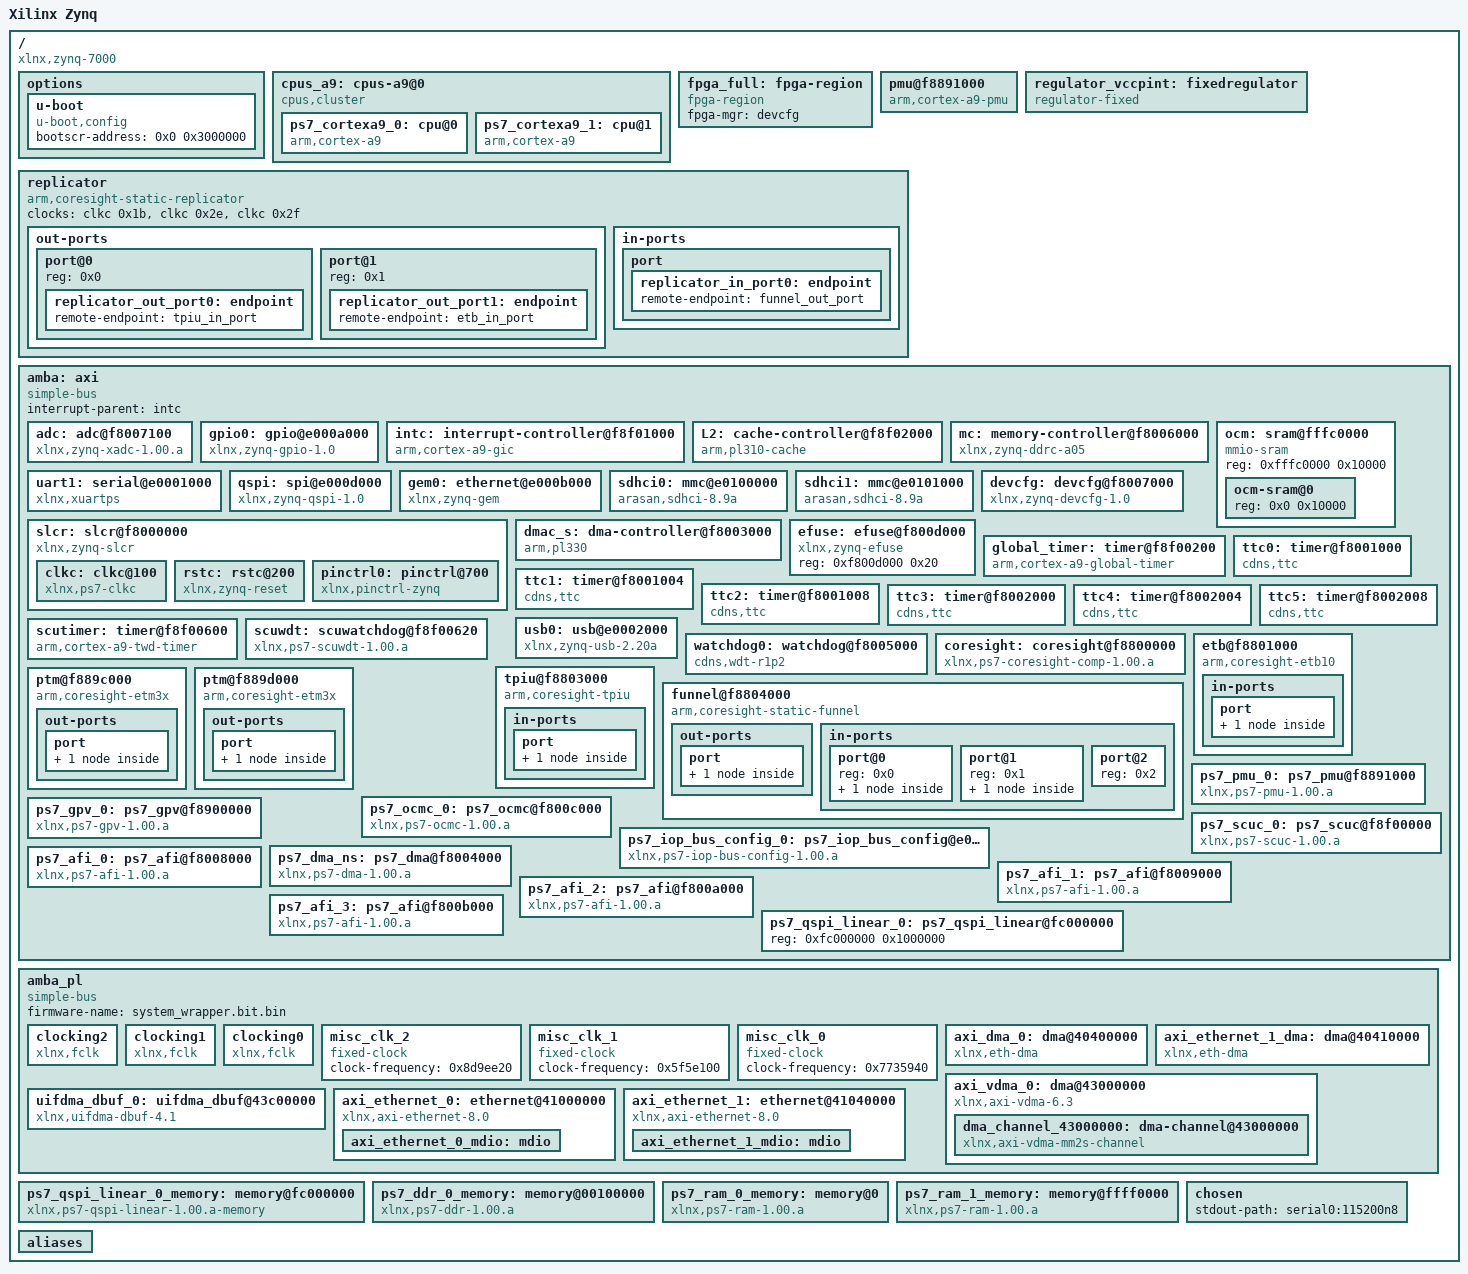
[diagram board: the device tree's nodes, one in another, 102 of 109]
/dts-v1/;
/ {
        #address-cells = <0x1>;
        #size-cells = <0x1>;
        compatible = "xlnx,zynq-7000";
        model = "Xilinx Zynq";
        device_id = "7z020";
        slrcount = <0x1>;
        family = "Zynq";
        speed_grade = "2";
        pruned-sdt = <0x1>;

        options {

                u-boot {
                        compatible = "u-boot,config";
                        bootscr-address = <0x0 0x3000000>;
                };
        };

        cpus_a9: cpus-a9@0 {
                phandle = <0x39>;
                #address-cells = <0x1>;
                #size-cells = <0x0>;
                compatible = "cpus,cluster";
                address-map = <0xf0000000 &amba 0xf0000000 0x10000000>,
                 <0x100000 &ps7_ddr_0_memory 0x100000 0x3ff00000>,
                 <0x0 &ps7_ram_0_memory 0x0 0x30000>,
                 <0xffff0000 &ps7_ram_1_memory 0xffff0000 0xfe00>,
                 <0x40400000 &axi_dma_0 0x40400000 0x10000>,
                 <0x40410000 &axi_ethernet_1_dma 0x40410000 0x10000>,
                 <0x41000000 &axi_ethernet_0 0x41000000 0x40000>,
                 <0x41040000 &axi_ethernet_1 0x41040000 0x40000>,
                 <0x43000000 &axi_vdma_0 0x43000000 0x10000>,
                 <0x43c00000 &uifdma_dbuf_0 0x43c00000 0x10000>,
                 <0xf8008000 &ps7_afi_0 0xf8008000 0x1000>,
                 <0xf8009000 &ps7_afi_1 0xf8009000 0x1000>,
                 <0xf800a000 &ps7_afi_2 0xf800a000 0x1000>,
                 <0xf800b000 &ps7_afi_3 0xf800b000 0x1000>,
                 <0xf8800000 &coresight 0xf8800000 0x100000>,
                 <0xf8006000 &mc 0xf8006000 0x1000>,
                 <0xf8007000 &devcfg 0xf8007000 0x100>,
                 <0xf8004000 &ps7_dma_ns 0xf8004000 0x1000>,
                 <0xf8003000 &dmac_s 0xf8003000 0x1000>,
                 <0xe000b000 &gem0 0xe000b000 0x1000>,
                 <0xf8f00200 &global_timer 0xf8f00200 0x100>,
                 <0xe000a000 &gpio0 0xe000a000 0x1000>,
                 <0xf8900000 &ps7_gpv_0 0xf8900000 0x100000>,
                 <0xf8f01000 &intc 0xf8f01000 0x1000>,
                 <0xe0200000 &ps7_iop_bus_config_0 0xe0200000 0x1000>,
                 <0xf8f02000 &L2 0xf8f02000 0x1000>,
                 <0xf800c000 &ps7_ocmc_0 0xf800c000 0x1000>,
                 <0xf8891000 &ps7_pmu_0 0xf8891000 0x1000>,
                 <0xe000d000 &qspi 0xe000d000 0x1000>,
                 <0xfc000000 &ps7_qspi_linear_0_memory 0xfc000000 0x1000000>,
                 <0xf8f00000 &ps7_scuc_0 0xf8f00000 0xfd>,
                 <0xf8f00600 &scutimer 0xf8f00600 0x20>,
                 <0xf8f00620 &scuwdt 0xf8f00620 0xe0>,
                 <0xe0100000 &sdhci0 0xe0100000 0x1000>,
                 <0xe0101000 &sdhci1 0xe0101000 0x1000>,
                 <0xf8000000 &slcr 0xf8000000 0x1000>,
                 <0xe0001000 &uart1 0xe0001000 0x1000>,
                 <0xe0002000 &usb0 0xe0002000 0x1000>,
                 <0xf8007100 &adc 0xf8007100 0x21>;
                #ranges-address-cells = <0x1>;
                #ranges-size-cells = <0x1>;

                ps7_cortexa9_0: cpu@0 {
                        phandle = <0x32>;
                        compatible = "arm,cortex-a9";
                        device_type = "cpu";
                        reg = <0x0>;
                        clocks = <&clkc 0x3>;
                        clock-latency = <0x3e8>;
                        cpu0-supply = <&regulator_vccpint>;
                        operating-points = <0xa2c2b 0xf4240 0x51616 0xf4240>;
                        xlnx,i-cache-size = <0x8000>;
                        xlnx,d-cache-line-size = <0x14>;
                        xlnx,i-cache-line-size = <0x14>;
                        xlnx,cpu-1x-clk-freq-hz = <0x69f6bcb>;
                        xlnx,ip-name = "ps7_cortexa9";
                        xlnx,d-cache-size = <0x8000>;
                        xlnx,num-cores = <0x2>;
                        xlnx,cpu-clk-freq-hz = <0x27bc86bf>;
                        bus-handle = <0x1>;
                };

                ps7_cortexa9_1: cpu@1 {
                        phandle = <0x34>;
                        compatible = "arm,cortex-a9";
                        device_type = "cpu";
                        reg = <0x1>;
                        clocks = <&clkc 0x3>;
                        xlnx,i-cache-size = <0x8000>;
                        xlnx,d-cache-line-size = <0x14>;
                        xlnx,i-cache-line-size = <0x14>;
                        xlnx,cpu-1x-clk-freq-hz = <0x69f6bcb>;
                        xlnx,ip-name = "ps7_cortexa9";
                        xlnx,d-cache-size = <0x8000>;
                        xlnx,cpu-clk-freq-hz = <0x27bc86bf>;
                        bus-handle = <0x1>;
                };
        };

        fpga_full: fpga-region {
                phandle = <0x3a>;
                compatible = "fpga-region";
                fpga-mgr = <&devcfg>;
                #address-cells = <0x1>;
                #size-cells = <0x1>;
                ranges;
        };

        pmu@f8891000 {
                compatible = "arm,cortex-a9-pmu";
                interrupts = <0x0 0x5 0x4 0x0 0x6 0x4>;
                interrupt-parent = <&intc>;
                reg = <0xf8891000 0x1000 0xf8893000 0x1000>;
        };

        regulator_vccpint: fixedregulator {
                phandle = <0x29>;
                compatible = "regulator-fixed";
                regulator-name = "VCCPINT";
                regulator-min-microvolt = <0xf4240>;
                regulator-max-microvolt = <0xf4240>;
                regulator-boot-on;
                regulator-always-on;
        };

        replicator {
                compatible = "arm,coresight-static-replicator";
                clocks = <&clkc 0x1b>,
                 <&clkc 0x2e>,
                 <&clkc 0x2f>;
                clock-names = "apb_pclk", "dbg_trc", "dbg_apb";

                out-ports {
                        #address-cells = <0x1>;
                        #size-cells = <0x0>;

                        port@0 {
                                reg = <0x0>;

                                replicator_out_port0: endpoint {
                                        phandle = <0x2e>;
                                        remote-endpoint = <&tpiu_in_port>;
                                };
                        };

                        port@1 {
                                reg = <0x1>;

                                replicator_out_port1: endpoint {
                                        phandle = <0x2d>;
                                        remote-endpoint = <&etb_in_port>;
                                };
                        };
                };

                in-ports {

                        port {

                                replicator_in_port0: endpoint {
                                        phandle = <0x2f>;
                                        remote-endpoint = <&funnel_out_port>;
                                };
                        };
                };
        };

        amba: axi {
                phandle = <0x1>;
                bootph-all;
                compatible = "simple-bus";
                #address-cells = <0x1>;
                #size-cells = <0x1>;
                interrupt-parent = <&intc>;
                ranges;

                adc: adc@f8007100 {
                        phandle = <0x27>;
                        compatible = "xlnx,zynq-xadc-1.00.a";
                        reg = <0xf8007100 0x20>;
                        interrupts = <0x0 0x7 0x4>;
                        interrupt-parent = <&intc>;
                        clocks = <&clkc 0xc>;
                        status = "okay";
                        xlnx,ip-name = "ps7_xadc";
                        xlnx,name = "ps7_xadc_0";
                };

                gpio0: gpio@e000a000 {
                        phandle = <0x16>;
                        compatible = "xlnx,zynq-gpio-1.0";
                        #gpio-cells = <0x2>;
                        clocks = <&clkc 0x2a>;
                        gpio-controller;
                        interrupt-controller;
                        #interrupt-cells = <0x2>;
                        interrupt-parent = <&intc>;
                        interrupts = <0x0 0x14 0x4>;
                        reg = <0xe000a000 0x1000>;
                        xlnx,mio-gpio-mask = <0x5600>;
                        status = "okay";
                        gpio-mask-high = <0x0>;
                        xlnx,emio-gpio-width = <0x40>;
                        xlnx,ip-name = "ps7_gpio";
                        gpio-mask-low = <0x5600>;
                        emio-gpio-width = <0x40>;
                        xlnx,name = "ps7_gpio_0";
                };

                intc: interrupt-controller@f8f01000 {
                        phandle = <0x18>;
                        compatible = "arm,cortex-a9-gic";
                        #interrupt-cells = <0x3>;
                        interrupt-controller;
                        reg = <0xf8f01000 0x1000 0xf8f00100 0x100>;
                        status = "okay";
                        xlnx,irq-f2p-mode = "DIRECT";
                        xlnx,ip-name = "ps7_intc_dist";
                        xlnx,name = "ps7_intc_dist_0";
                };

                L2: cache-controller@f8f02000 {
                        phandle = <0x1a>;
                        compatible = "arm,pl310-cache";
                        reg = <0xf8f02000 0x1000>;
                        interrupts = <0x0 0x2 0x4>;
                        arm,data-latency = <0x3 0x2 0x2>;
                        arm,tag-latency = <0x2 0x2 0x2>;
                        cache-unified;
                        cache-level = <0x2>;
                        status = "okay";
                        xlnx,ip-name = "ps7_pl310";
                        xlnx,name = "ps7_pl310_0";
                };

                mc: memory-controller@f8006000 {
                        phandle = <0x10>;
                        compatible = "xlnx,zynq-ddrc-a05";
                        reg = <0xf8006000 0x1000>;
                        status = "okay";
                        xlnx,ddr-clk-freq-hz = <0x1fca057e>;
                        xlnx,ip-name = "ps7_ddrc";
                        xlnx,has-ecc = <0x0>;
                        xlnx,name = "ps7_ddrc_0";
                };

                ocm: sram@fffc0000 {
                        phandle = <0x3f>;
                        compatible = "mmio-sram";
                        reg = <0xfffc0000 0x10000>;
                        #address-cells = <0x1>;
                        #size-cells = <0x1>;
                        ranges = <0x0 0xfffc0000 0x10000>;

                        ocm-sram@0 {
                                reg = <0x0 0x10000>;
                        };
                };

                uart1: serial@e0001000 {
                        phandle = <0x25>;
                        compatible = "xlnx,xuartps", "cdns,uart-r1p8";
                        status = "okay";
                        clocks = <&clkc 0x18>,
                         <&clkc 0x29>;
                        clock-names = "uart_clk", "pclk";
                        reg = <0xe0001000 0x1000>;
                        interrupts = <0x0 0x32 0x4>;
                        interrupt-parent = <&intc>;
                        xlnx,clock-freq = <0x5f5e100>;
                        xlnx,has-modem = <0x0>;
                        xlnx,ip-name = "ps7_uart";
                        cts-override;
                        port-number = <0x0>;
                        xlnx,uart-clk-freq-hz = <0x5f5e100>;
                        xlnx,name = "ps7_uart_1";
                };

                qspi: spi@e000d000 {
                        phandle = <0x1d>;
                        compatible = "xlnx,zynq-qspi-1.0";
                        reg = <0xe000d000 0x1000>;
                        interrupt-parent = <&intc>;
                        interrupts = <0x0 0x13 0x4>;
                        clocks = <&clkc 0xa>,
                         <&clkc 0x2b>;
                        clock-names = "ref_clk", "pclk";
                        status = "okay";
                        #address-cells = <0x1>;
                        #size-cells = <0x0>;
                        xlnx,qspi-fbclk = <0x0>;
                        num-cs = <0x1>;
                        xlnx,qspi-clk-freq-hz = <0x7735940>;
                        xlnx,bus-width = <0x2>;
                        xlnx,ip-name = "ps7_qspi";
                        spi-rx-bus-width = <0x4>;
                        xlnx,connection-mode = <0x0>;
                        spi-tx-bus-width = <0x4>;
                        xlnx,clock-freq = <0x7735940>;
                        xlnx,fb-clk = <0x1>;
                        xlnx,qspi-mode = <0x0>;
                        xlnx,name = "ps7_qspi_0";
                        xlnx,qspi-bus-width = <0x2>;
                        is-dual = <0x0>;
                };

                gem0: ethernet@e000b000 {
                        phandle = <0x14>;
                        compatible = "xlnx,zynq-gem", "cdns,gem";
                        reg = <0xe000b000 0x1000>;
                        status = "okay";
                        interrupts = <0x0 0x16 0x4>;
                        interrupt-parent = <&intc>;
                        clocks = <&clkc 0x1e>,
                         <&clkc 0x1e>,
                         <&clkc 0xd>;
                        clock-names = "pclk", "hclk", "tx_clk";
                        #address-cells = <0x1>;
                        #size-cells = <0x0>;
                        xlnx,has-mdio = <0x1>;
                        phy-mode = "rgmii-id";
                        xlnx,enet-slcr-1000mbps-div0 = <0x8>;
                        xlnx,enet-slcr-10mbps-div0 = <0x8>;
                        xlnx,enet-slcr-1000mbps-div1 = <0x1>;
                        xlnx,enet-slcr-10mbps-div1 = <0x32>;
                        xlnx,ip-name = "ps7_ethernet";
                        xlnx,eth-mode = <0x1>;
                        xlnx,enet-clk-freq-hz = <0x7735940>;
                        xlnx,enet-slcr-100mbps-div0 = <0x8>;
                        xlnx,ptp-enet-clock = <0x69f6bcb>;
                        xlnx,enet-slcr-100mbps-div1 = <0x5>;
                        xlnx,name = "ps7_ethernet_0";
                };

                sdhci0: mmc@e0100000 {
                        phandle = <0x22>;
                        compatible = "arasan,sdhci-8.9a";
                        status = "okay";
                        clock-names = "clk_xin", "clk_ahb";
                        clocks = <&clkc 0x15>,
                         <&clkc 0x20>;
                        interrupt-parent = <&intc>;
                        interrupts = <0x0 0x18 0x4>;
                        reg = <0xe0100000 0x1000>;
                        xlnx,has-power = <0x0>;
                        xlnx,ip-name = "ps7_sdio";
                        xlnx,sdio-clk-freq-hz = <0x2faf080>;
                        xlnx,has-wp = <0x0>;
                        xlnx,has-cd = <0x1>;
                        xlnx,name = "ps7_sd_0";
                };

                sdhci1: mmc@e0101000 {
                        phandle = <0x23>;
                        compatible = "arasan,sdhci-8.9a";
                        status = "okay";
                        clock-names = "clk_xin", "clk_ahb";
                        clocks = <&clkc 0x16>,
                         <&clkc 0x21>;
                        interrupt-parent = <&intc>;
                        interrupts = <0x0 0x2f 0x4>;
                        reg = <0xe0101000 0x1000>;
                        xlnx,has-power = <0x0>;
                        xlnx,ip-name = "ps7_sdio";
                        xlnx,sdio-clk-freq-hz = <0x2faf080>;
                        xlnx,has-wp = <0x0>;
                        xlnx,has-cd = <0x1>;
                        xlnx,name = "ps7_sd_1";
                };

                slcr: slcr@f8000000 {
                        phandle = <0x24>;
                        bootph-all;
                        #address-cells = <0x1>;
                        #size-cells = <0x1>;
                        compatible = "xlnx,zynq-slcr", "syscon", "simple-mfd";
                        reg = <0xf8000000 0x1000>;
                        ranges;
                        status = "okay";
                        xlnx,ip-name = "ps7_slcr";
                        xlnx,name = "ps7_slcr_0";

                        clkc: clkc@100 {
                                phandle = <0x28>;
                                bootph-all;
                                #clock-cells = <0x1>;
                                compatible = "xlnx,ps7-clkc";
                                fclk-enable = <0x7>;
                                clock-output-names = "armpll", "ddrpll", "iopll", "cpu_6or4x", "cpu_3or2x", "cpu_2x", "cpu_1x", "ddr2x", "ddr3x", "dci", "lqspi", "smc", "pcap", "gem0", "gem1", "fclk0", "fclk1", "fclk2", "fclk3", "can0", "can1", "sdio0", "sdio1", "uart0", "uart1", "spi0", "spi1", "dma", "usb0_aper", "usb1_aper", "gem0_aper", "gem1_aper", "sdio0_aper", "sdio1_aper", "spi0_aper", "spi1_aper", "can0_aper", "can1_aper", "i2c0_aper", "i2c1_aper", "uart0_aper", "uart1_aper", "gpio_aper", "lqspi_aper", "smc_aper", "swdt", "dbg_trc", "dbg_apb";
                                reg = <0x100 0x100>;
                                ps-clk-frequency = <0x1fca055>;
                        };

                        rstc: rstc@200 {
                                phandle = <0x47>;
                                compatible = "xlnx,zynq-reset";
                                reg = <0x200 0x48>;
                                #reset-cells = <0x1>;
                                syscon = <&slcr>;
                        };

                        pinctrl0: pinctrl@700 {
                                phandle = <0x48>;
                                compatible = "xlnx,pinctrl-zynq";
                                reg = <0x700 0x200>;
                                syscon = <&slcr>;
                        };
                };

                dmac_s: dma-controller@f8003000 {
                        phandle = <0x13>;
                        compatible = "arm,pl330", "arm,primecell";
                        reg = <0xf8003000 0x1000>;
                        interrupt-parent = <&intc>;
                        interrupts = <0x0 0xd 0x4 0x0 0xe 0x4 0x0 0xf 0x4 0x0 0x10 0x4 0x0 0x11 0x4 0x0 0x28 0x4 0x0 0x29 0x4 0x0 0x2a 0x4 0x0 0x2b 0x4>;
                        #dma-cells = <0x1>;
                        clocks = <&clkc 0x1b>;
                        clock-names = "apb_pclk";
                        status = "okay";
                        xlnx,ip-name = "ps7_dma";
                        xlnx,is-secure;
                        xlnx,name = "ps7_dma_s";
                };

                devcfg: devcfg@f8007000 {
                        phandle = <0x11>;
                        compatible = "xlnx,zynq-devcfg-1.0";
                        reg = <0xf8007000 0x100>;
                        interrupt-parent = <&intc>;
                        interrupts = <0x0 0x8 0x4>;
                        clocks = <&clkc 0xc>,
                         <&clkc 0xf>,
                         <&clkc 0x10>,
                         <&clkc 0x11>,
                         <&clkc 0x12>;
                        clock-names = "ref_clk", "fclk0", "fclk1", "fclk2", "fclk3";
                        syscon = <&slcr>;
                        status = "okay";
                        xlnx,ip-name = "ps7_dev_cfg";
                        xlnx,name = "ps7_dev_cfg_0";
                };

                efuse: efuse@f800d000 {
                        phandle = <0x49>;
                        compatible = "xlnx,zynq-efuse";
                        reg = <0xf800d000 0x20>;
                };

                global_timer: timer@f8f00200 {
                        phandle = <0x15>;
                        compatible = "arm,cortex-a9-global-timer";
                        reg = <0xf8f00200 0x20>;
                        interrupts = <0x1 0xb 0x301>;
                        interrupt-parent = <&intc>;
                        clocks = <&clkc 0x4>;
                        status = "okay";
                        xlnx,ip-name = "ps7_globaltimer";
                        xlnx,name = "ps7_globaltimer_0";
                };

                ttc0: timer@f8001000 {
                        phandle = <0x4a>;
                        interrupt-parent = <&intc>;
                        interrupts = <0x0 0xa 0x4 0x0 0xb 0x4 0x0 0xc 0x4>;
                        compatible = "cdns,ttc";
                        clocks = <&clkc 0x6>;
                        reg = <0xf8001000 0x1000>;
                };

                ttc1: timer@f8001004 {
                        phandle = <0x5c>;
                        reg = <0xf8001004 0xffc>;
                        clocks = <&clkc 0x6>;
                        compatible = "cdns,ttc";
                        interrupts = <0x0 0xb 0x4 0x0 0xc 0x4>;
                        interrupt-parent = <&intc>;
                        lop-dynamic-ttc-node = <0x1>;
                };

                ttc2: timer@f8001008 {
                        phandle = <0x5d>;
                        reg = <0xf8001008 0xff8>;
                        clocks = <&clkc 0x6>;
                        compatible = "cdns,ttc";
                        interrupts = <0x0 0xc 0x4>;
                        interrupt-parent = <&intc>;
                        lop-dynamic-ttc-node = <0x1>;
                };

                ttc3: timer@f8002000 {
                        phandle = <0x4b>;
                        interrupt-parent = <&intc>;
                        interrupts = <0x0 0x25 0x4 0x0 0x26 0x4 0x0 0x27 0x4>;
                        compatible = "cdns,ttc";
                        clocks = <&clkc 0x6>;
                        reg = <0xf8002000 0x1000>;
                };

                ttc4: timer@f8002004 {
                        phandle = <0x5e>;
                        reg = <0xf8002004 0xffc>;
                        clocks = <&clkc 0x6>;
                        compatible = "cdns,ttc";
                        interrupts = <0x0 0x26 0x4 0x0 0x27 0x4>;
                        interrupt-parent = <&intc>;
                        lop-dynamic-ttc-node = <0x1>;
                };

                ttc5: timer@f8002008 {
                        phandle = <0x5f>;
                        reg = <0xf8002008 0xff8>;
                        clocks = <&clkc 0x6>;
                        compatible = "cdns,ttc";
                        interrupts = <0x0 0x27 0x4>;
                        interrupt-parent = <&intc>;
                        lop-dynamic-ttc-node = <0x1>;
                };

                scutimer: timer@f8f00600 {
                        phandle = <0x20>;
                        bootph-all;
                        interrupt-parent = <&intc>;
                        interrupts = <0x1 0xd 0x301>;
                        compatible = "arm,cortex-a9-twd-timer";
                        reg = <0xf8f00600 0x20>;
                        clocks = <&clkc 0x4>;
                        status = "okay";
                        xlnx,ip-name = "ps7_scutimer";
                        xlnx,name = "ps7_scutimer_0";
                };

                scuwdt: scuwatchdog@f8f00620 {
                        phandle = <0x21>;
                        interrupt-parent = <&intc>;
                        interrupts = <0x1 0xe 0x4>;
                        compatible = "xlnx,ps7-scuwdt-1.00.a";
                        reg = <0xf8f00620 0xe0>;
                        status = "okay";
                        xlnx,ip-name = "ps7_scuwdt";
                        xlnx,name = "ps7_scuwdt_0";
                };

                usb0: usb@e0002000 {
                        phandle = <0x26>;
                        compatible = "xlnx,zynq-usb-2.20a", "chipidea,usb2";
                        status = "okay";
                        clocks = <&clkc 0x1c>;
                        interrupt-parent = <&intc>;
                        interrupts = <0x0 0x15 0x4>;
                        reg = <0xe0002000 0x1000>;
                        phy_type = "ulpi";
                        xlnx,ip-name = "ps7_usb";
                        xlnx,enable-superspeed = <0x0>;
                        xlnx,name = "ps7_usb_0";
                };

                watchdog0: watchdog@f8005000 {
                        phandle = <0x4d>;
                        clocks = <&clkc 0x2d>;
                        compatible = "cdns,wdt-r1p2";
                        interrupt-parent = <&intc>;
                        interrupts = <0x0 0x9 0x1>;
                        reg = <0xf8005000 0x1000>;
                        timeout-sec = <0xa>;
                };

                coresight: coresight@f8800000 {
                        phandle = <0xf>;
                        compatible = "xlnx,ps7-coresight-comp-1.00.a";
                        status = "okay";
                        reg = <0xf8800000 0x100000>;
                        xlnx,ip-name = "ps7_coresight_comp";
                        xlnx,name = "ps7_coresight_comp_0";
                };

                etb@f8801000 {
                        compatible = "arm,coresight-etb10", "arm,primecell";
                        reg = <0xf8801000 0x1000>;
                        clocks = <&clkc 0x1b>,
                         <&clkc 0x2e>,
                         <&clkc 0x2f>;
                        clock-names = "apb_pclk", "dbg_trc", "dbg_apb";

                        in-ports {

                                port {

                                        etb_in_port: endpoint {
                                                phandle = <0x2b>;
                                                remote-endpoint = <&replicator_out_port1>;
                                        };
                                };
                        };
                };

                tpiu@f8803000 {
                        compatible = "arm,coresight-tpiu", "arm,primecell";
                        reg = <0xf8803000 0x1000>;
                        clocks = <&clkc 0x1b>,
                         <&clkc 0x2e>,
                         <&clkc 0x2f>;
                        clock-names = "apb_pclk", "dbg_trc", "dbg_apb";

                        in-ports {

                                port {

                                        tpiu_in_port: endpoint {
                                                phandle = <0x2a>;
                                                remote-endpoint = <&replicator_out_port0>;
                                        };
                                };
                        };
                };

                funnel@f8804000 {
                        compatible = "arm,coresight-static-funnel", "arm,primecell";
                        reg = <0xf8804000 0x1000>;
                        clocks = <&clkc 0x1b>,
                         <&clkc 0x2e>,
                         <&clkc 0x2f>;
                        clock-names = "apb_pclk", "dbg_trc", "dbg_apb";

                        out-ports {

                                port {

                                        funnel_out_port: endpoint {
                                                phandle = <0x2c>;
                                                remote-endpoint = <&replicator_in_port0>;
                                        };
                                };
                        };

                        in-ports {
                                #address-cells = <0x1>;
                                #size-cells = <0x0>;

                                port@0 {
                                        reg = <0x0>;

                                        funnel0_in_port0: endpoint {
                                                phandle = <0x33>;
                                                remote-endpoint = <&ptm0_out_port>;
                                        };
                                };

                                port@1 {
                                        reg = <0x1>;

                                        funnel0_in_port1: endpoint {
                                                phandle = <0x35>;
                                                remote-endpoint = <&ptm1_out_port>;
                                        };
                                };

                                port@2 {
                                        reg = <0x2>;
                                };
                        };
                };

                ptm@f889c000 {
                        compatible = "arm,coresight-etm3x", "arm,primecell";
                        reg = <0xf889c000 0x1000>;
                        clocks = <&clkc 0x1b>,
                         <&clkc 0x2e>,
                         <&clkc 0x2f>;
                        clock-names = "apb_pclk", "dbg_trc", "dbg_apb";
                        cpu = <&ps7_cortexa9_0>;

                        out-ports {

                                port {

                                        ptm0_out_port: endpoint {
                                                phandle = <0x30>;
                                                remote-endpoint = <&funnel0_in_port0>;
                                        };
                                };
                        };
                };

                ptm@f889d000 {
                        compatible = "arm,coresight-etm3x", "arm,primecell";
                        reg = <0xf889d000 0x1000>;
                        clocks = <&clkc 0x1b>,
                         <&clkc 0x2e>,
                         <&clkc 0x2f>;
                        clock-names = "apb_pclk", "dbg_trc", "dbg_apb";
                        cpu = <&ps7_cortexa9_1>;

                        out-ports {

                                port {

                                        ptm1_out_port: endpoint {
                                                phandle = <0x31>;
                                                remote-endpoint = <&funnel0_in_port1>;
                                        };
                                };
                        };
                };

                ps7_pmu_0: ps7_pmu@f8891000 {
                        phandle = <0x1c>;
                        compatible = "xlnx,ps7-pmu-1.00.a";
                        status = "okay";
                        xlnx,ip-name = "ps7_pmu";
                        reg = <0xf8891000 0x1000 0xf8893000 0x1000>;
                        xlnx,name = "ps7_pmu_0";
                };

                ps7_ocmc_0: ps7_ocmc@f800c000 {
                        phandle = <0x1b>;
                        compatible = "xlnx,ps7-ocmc-1.00.a";
                        status = "okay";
                        xlnx,ip-name = "ps7_ocmc";
                        reg = <0xf800c000 0x1000>;
                        xlnx,name = "ps7_ocmc_0";
                };

                ps7_gpv_0: ps7_gpv@f8900000 {
                        phandle = <0x17>;
                        compatible = "xlnx,ps7-gpv-1.00.a";
                        status = "okay";
                        xlnx,ip-name = "ps7_gpv";
                        reg = <0xf8900000 0x100000>;
                        xlnx,name = "ps7_gpv_0";
                };

                ps7_scuc_0: ps7_scuc@f8f00000 {
                        phandle = <0x1f>;
                        compatible = "xlnx,ps7-scuc-1.00.a";
                        status = "okay";
                        xlnx,ip-name = "ps7_scuc";
                        reg = <0xf8f00000 0xfd>;
                        xlnx,name = "ps7_scuc_0";
                };

                ps7_iop_bus_config_0: ps7_iop_bus_config@e0200000 {
                        phandle = <0x19>;
                        compatible = "xlnx,ps7-iop-bus-config-1.00.a";
                        status = "okay";
                        xlnx,ip-name = "ps7_iop_bus_config";
                        reg = <0xe0200000 0x1000>;
                        xlnx,name = "ps7_iop_bus_config_0";
                };

                ps7_dma_ns: ps7_dma@f8004000 {
                        phandle = <0x12>;
                        compatible = "xlnx,ps7-dma-1.00.a";
                        status = "okay";
                        xlnx,ip-name = "ps7_dma";
                        xlnx,is-secure;
                        reg = <0xf8004000 0x1000>;
                        xlnx,name = "ps7_dma_ns";
                };

                ps7_afi_0: ps7_afi@f8008000 {
                        phandle = <0xb>;
                        compatible = "xlnx,ps7-afi-1.00.a";
                        status = "okay";
                        xlnx,ip-name = "ps7_afi";
                        reg = <0xf8008000 0x1000>;
                        xlnx,name = "ps7_afi_0";
                };

                ps7_afi_1: ps7_afi@f8009000 {
                        phandle = <0xc>;
                        compatible = "xlnx,ps7-afi-1.00.a";
                        status = "okay";
                        xlnx,ip-name = "ps7_afi";
                        reg = <0xf8009000 0x1000>;
                        xlnx,name = "ps7_afi_1";
                };

                ps7_afi_2: ps7_afi@f800a000 {
                        phandle = <0xd>;
                        compatible = "xlnx,ps7-afi-1.00.a";
                        status = "okay";
                        xlnx,ip-name = "ps7_afi";
                        reg = <0xf800a000 0x1000>;
                        xlnx,name = "ps7_afi_2";
                };

                ps7_afi_3: ps7_afi@f800b000 {
                        phandle = <0xe>;
                        compatible = "xlnx,ps7-afi-1.00.a";
                        status = "okay";
                        xlnx,ip-name = "ps7_afi";
                        reg = <0xf800b000 0x1000>;
                        xlnx,name = "ps7_afi_3";
                };

                ps7_qspi_linear_0: ps7_qspi_linear@fc000000 {
                        phandle = <0x53>;
                        reg = <0xfc000000 0x1000000>;
                };
        };

        amba_pl: amba_pl {
                phandle = <0x54>;
                ranges;
                compatible = "simple-bus";
                #address-cells = <0x1>;
                #size-cells = <0x1>;
                firmware-name = "system_wrapper.bit.bin";

                clocking2: clocking2 {
                        phandle = <0x55>;
                        compatible = "xlnx,fclk";
                        assigned-clocks = <&clkc 0x11>;
                        assigned-clock-rates = <0xbebc200>;
                        #clock-cells = <0x0>;
                        clock-output-names = "fabric_clk";
                        clocks = <&clkc 0x11>;
                };

                clocking1: clocking1 {
                        phandle = <0x56>;
                        compatible = "xlnx,fclk";
                        assigned-clocks = <&clkc 0x10>;
                        assigned-clock-rates = <0x7735940>;
                        #clock-cells = <0x0>;
                        clock-output-names = "fabric_clk";
                        clocks = <&clkc 0x10>;
                };

                clocking0: clocking0 {
                        phandle = <0x57>;
                        compatible = "xlnx,fclk";
                        assigned-clocks = <&clkc 0xf>;
                        assigned-clock-rates = <0x5f5e100>;
                        #clock-cells = <0x0>;
                        clock-output-names = "fabric_clk";
                        clocks = <&clkc 0xf>;
                };

                misc_clk_2: misc_clk_2 {
                        phandle = <0x37>;
                        compatible = "fixed-clock";
                        clock-frequency = <0x8d9ee20>;
                        #clock-cells = <0x0>;
                };

                misc_clk_1: misc_clk_1 {
                        phandle = <0x36>;
                        compatible = "fixed-clock";
                        clock-frequency = <0x5f5e100>;
                        #clock-cells = <0x0>;
                };

                misc_clk_0: misc_clk_0 {
                        phandle = <0x38>;
                        compatible = "fixed-clock";
                        clock-frequency = <0x7735940>;
                        #clock-cells = <0x0>;
                };

                axi_dma_0: dma@40400000 {
                        phandle = <0x5>;
                        interrupts = <0x0 0x1d 0x4 0x0 0x1e 0x4>;
                        compatible = "xlnx,eth-dma";
                        xlnx,s2mm-data-width = <0x40>;
                        xlnx,mm2s-burst-size = <0x8>;
                        xlnx,m-axi-mm2s-data-width = <0x40>;
                        xlnx,num-s2mm-channels = <0x1>;
                        xlnx,dlytmr-resolution = <0x7d>;
                        axistream-control-connected = <&axi_ethernet_0>;
                        interrupt-parent = <&intc>;
                        xlnx,sg-length-width = <0x10>;
                        xlnx,prmry-is-aclk-async = <0x0>;
                        xlnx,include-s2mm-sf = <0x1>;
                        #dma-cells = <0x1>;
                        xlnx,ip-name = "axi_dma";
                        xlnx,single-interface = <0x0>;
                        xlnx,sg-include-stscntrl-strm = <0x1>;
                        xlnx,include-s2mm-dre = <0x1>;
                        reg = <0x40400000 0x10000>;
                        xlnx,addr-width = <0x20>;
                        xlnx,include-s2mm = <0x1>;
                        clocks = <&clkc 0xf>,
                         <&clkc 0xf>,
                         <&clkc 0xf>,
                         <&clkc 0xf>;
                        xlnx,s-axis-s2mm-tdata-width = <0x20>;
                        xlnx,micro-dma = <0x0>;
                        xlnx,increase-throughput = <0x0>;
                        xlnx,mm2s-data-width = <0x40>;
                        xlnx,addrwidth = <0x20>;
                        xlnx,sg-use-stsapp-length = <0x1>;
                        xlnx,m-axis-mm2s-tdata-width = <0x20>;
                        xlnx,include-dre;
                        xlnx,edk-iptype = "PERIPHERAL";
                        xlnx,s2mm-burst-size = <0x10>;
                        xlnx,m-axi-s2mm-data-width = <0x40>;
                        xlnx,num-queues = /bits/ 16 <0x0001>;
                        xlnx,num-mm2s-channels = <0x1>;
                        xlnx,enable-multi-channel = <0x0>;
                        status = "okay";
                        xlnx,include-mm2s-sf = <0x1>;
                        clock-names = "m_axi_mm2s_aclk", "m_axi_s2mm_aclk", "m_axi_sg_aclk", "s_axi_lite_aclk";
                        axistream-connected = <&axi_ethernet_0>;
                        interrupt-names = "mm2s_introut", "s2mm_introut";
                        xlnx,include-mm2s = <0x1>;
                        xlnx,include-mm2s-dre = <0x1>;
                        xlnx,name = "axi_dma_0";
                };

                axi_ethernet_1_dma: dma@40410000 {
                        phandle = <0x6>;
                        interrupts = <0x0 0x23 0x4 0x0 0x24 0x4>;
                        compatible = "xlnx,eth-dma";
                        xlnx,s2mm-data-width = <0x20>;
                        xlnx,mm2s-burst-size = <0x10>;
                        xlnx,m-axi-mm2s-data-width = <0x20>;
                        xlnx,num-s2mm-channels = <0x1>;
                        xlnx,dlytmr-resolution = <0x7d>;
                        axistream-control-connected = <&axi_ethernet_1>;
                        interrupt-parent = <&intc>;
                        xlnx,sg-length-width = <0x10>;
                        xlnx,prmry-is-aclk-async = <0x0>;
                        xlnx,include-s2mm-sf = <0x1>;
                        #dma-cells = <0x1>;
                        xlnx,ip-name = "axi_dma";
                        xlnx,single-interface = <0x0>;
                        xlnx,sg-include-stscntrl-strm = <0x1>;
                        xlnx,include-s2mm-dre = <0x1>;
                        reg = <0x40410000 0x10000>;
                        xlnx,addr-width = <0x20>;
                        xlnx,include-s2mm = <0x1>;
                        clocks = <&clkc 0xf>,
                         <&clkc 0xf>,
                         <&clkc 0xf>,
                         <&clkc 0xf>;
                        xlnx,s-axis-s2mm-tdata-width = <0x20>;
                        xlnx,micro-dma = <0x0>;
                        xlnx,increase-throughput = <0x0>;
                        xlnx,mm2s-data-width = <0x20>;
                        xlnx,addrwidth = <0x20>;
                        xlnx,sg-use-stsapp-length = <0x1>;
                        xlnx,m-axis-mm2s-tdata-width = <0x20>;
                        xlnx,include-dre;
                        xlnx,edk-iptype = "PERIPHERAL";
                        xlnx,s2mm-burst-size = <0x10>;
                        xlnx,m-axi-s2mm-data-width = <0x20>;
                        xlnx,num-queues = /bits/ 16 <0x0001>;
                        xlnx,num-mm2s-channels = <0x1>;
                        xlnx,enable-multi-channel = <0x0>;
                        status = "okay";
                        xlnx,include-mm2s-sf = <0x1>;
                        clock-names = "m_axi_mm2s_aclk", "m_axi_s2mm_aclk", "m_axi_sg_aclk", "s_axi_lite_aclk";
                        axistream-connected = <&axi_ethernet_1>;
                        interrupt-names = "mm2s_introut", "s2mm_introut";
                        xlnx,include-mm2s = <0x1>;
                        xlnx,include-mm2s-dre = <0x1>;
                        xlnx,name = "axi_ethernet_1_dma";
                };

                axi_vdma_0: dma@43000000 {
                        phandle = <0x9>;
                        xlnx,enable-debug-info-9 = <0x0>;
                        xlnx,enable-s2mm-frm-counter = <0x1>;
                        xlnx,enable-mm2s-delay-counter = <0x1>;
                        xlnx,dlytmr-resolution = <0x7d>;
                        xlnx,enable-s2mm-buf-full = <0x0>;
                        xlnx,ip-name = "axi_vdma";
                        xlnx,s2mm-genlock-num-masters = <0x1>;
                        reg = <0x43000000 0x10000>;
                        xlnx,enable-s2mm-fsync-out = <0x0>;
                        xlnx,use-mm2s-fsync = <0x0>;
                        xlnx,s2mm-linebuffer-thresh = <0x4>;
                        xlnx,enable-mm2s-frm-counter = <0x1>;
                        xlnx,m-axis-mm2s-tdata-width = <0x20>;
                        xlnx,enable-all = <0x0>;
                        xlnx,dynamic-resolution = <0x1>;
                        xlnx,enable-s2mm-rst-out = <0x0>;
                        interrupt-names = "mm2s_introut";
                        xlnx,s2mm-sof-enable = <0x1>;
                        xlnx,mm2s-genlock-num-masters = <0x1>;
                        xlnx,enable-mm2s-fsync-out = <0x0>;
                        xlnx,mm2s-linebuffer-thresh = <0x4>;
                        compatible = "xlnx,axi-vdma-6.3", "xlnx,axi-vdma-1.00.a";
                        xlnx,enable-tstvec = <0x0>;
                        interrupt-parent = <&intc>;
                        xlnx,s2mm-max-burst-length = <0x8>;
                        xlnx,enable-mm2s-rst-out = <0x0>;
                        xlnx,mm2s-sof-enable = <0x1>;
                        xlnx,include-s2mm-dre = <0x0>;
                        xlnx,enable-s2mm-frmstr-reg = <0x0>;
                        xlnx,m-axi-s2mm-data-width = <0x40>;
                        xlnx,enable-s2mm-sts-reg = <0x0>;
                        xlnx,mm2s-max-burst-length = <0x40>;
                        status = "okay";
                        xlnx,include-mm2s-dre = <0x0>;
                        xlnx,name = "axi_vdma_0";
                        xlnx,enable-mm2s-frmstr-reg = <0x0>;
                        interrupts = <0x0 0x34 0x4>;
                        xlnx,m-axi-mm2s-data-width = <0x40>;
                        xlnx,flush-on-fsync = <0x1>;
                        xlnx,include-s2mm-sf = <0x1>;
                        xlnx,single-interface = <0x0>;
                        xlnx,s2mm-linebuffer-depth = <0x200>;
                        xlnx,include-s2mm = <0x0>;
                        xlnx,addr-width = <0x40>;
                        clocks = <&clkc 0xf>,
                         <&clkc 0xf>,
                         <&clkc 0xf>;
                        xlnx,s-axis-s2mm-tdata-width = <0x20>;
                        xlnx,enable-debug-info-10 = <0x0>;
                        xlnx,addrwidth = <0x40>;
                        xlnx,enable-debug-info-11 = <0x0>;
                        xlnx,edk-iptype = "PERIPHERAL";
                        xlnx,enable-debug-info-12 = <0x0>;
                        xlnx,use-fsync = <0x1>;
                        xlnx,s2mm-genlock-repeat-en = <0x1>;
                        xlnx,enable-debug-info-13 = <0x0>;
                        xlnx,enable-vert-flip = <0x0>;
                        xlnx,include-mm2s-sf = <0x0>;
                        xlnx,enable-debug-info-14 = <0x1>;
                        xlnx,include-internal-genlock = <0x1>;
                        clock-names = "m_axi_mm2s_aclk", "m_axis_mm2s_aclk", "s_axi_lite_aclk";
                        xlnx,enable-debug-info-15 = <0x1>;
                        xlnx,mm2s-linebuffer-depth = <0x800>;
                        xlnx,include-mm2s = <0x1>;
                        xlnx,s2mm-genlock-mode = <0x0>;
                        xlnx,flush-fsync = <0x1>;
                        xlnx,select-xpm = <0x0>;
                        xlnx,s2mm-data-width = <0x40>;
                        xlnx,num-fstores = <0x1>;
                        xlnx,enable-s2mm-param-updt = <0x0>;
                        xlnx,enable-vidparam-reads = <0x1>;
                        xlnx,mm2s-genlock-repeat-en = <0x0>;
                        xlnx,prmry-is-aclk-async = <0x0>;
                        xlnx,s2mm-tdata-width = <0x20>;
                        #dma-cells = <0x1>;
                        xlnx,enable-vidprmtr-reads = <0x1>;
                        xlnx,mm2s-genlock-mode = <0x1>;
                        xlnx,enable-debug-info-0 = <0x0>;
                        xlnx,enable-debug-all = <0x0>;
                        xlnx,enable-debug-info-1 = <0x0>;
                        xlnx,mm2s-data-width = <0x40>;
                        xlnx,enable-debug-info-2 = <0x0>;
                        xlnx,enable-mm2s-param-updt = <0x0>;
                        xlnx,enable-debug-info-3 = <0x0>;
                        xlnx,enable-s2mm-delay-counter = <0x1>;
                        xlnx,enable-debug-info-4 = <0x0>;
                        xlnx,enable-debug-info-5 = <0x0>;
                        xlnx,mm2s-tdata-width = <0x20>;
                        xlnx,enable-debug-info-6 = <0x1>;
                        xlnx,enable-debug-info-7 = <0x1>;
                        xlnx,use-s2mm-fsync = <0x2>;
                        xlnx,enable-debug-info-8 = <0x0>;
                        xlnx,enable-mm2s-buf-empty = <0x0>;

                        dma_channel_43000000: dma-channel@43000000 {
                                phandle = <0x59>;
                                interrupts = <0x0 0x34 0x4>;
                                xlnx,datawidth = <0x20>;
                                xlnx,device-id = <0x0>;
                                compatible = "xlnx,axi-vdma-mm2s-channel";
                                xlnx,genlock-mode;
                        };
                };

                uifdma_dbuf_0: uifdma_dbuf@43c00000 {
                        phandle = <0xa>;
                        compatible = "xlnx,uifdma-dbuf-4.1";
                        xlnx,axi-lite;
                        xlnx,w-datawidth = <0x80>;
                        xlnx,w-xdiv = <0x2>;
                        xlnx,ip-name = "uifdma_dbuf";
                        xlnx,axi-addr-width = <0x20>;
                        xlnx,r-bufsize = <0x3>;
                        xlnx,r-dsizebits = <0x17>;
                        reg = <0x43c00000 0x10000>;
                        clocks = <&misc_clk_1>,
                         <&misc_clk_2>,
                         <&misc_clk_2>;
                        xlnx,r-xstride = <0x780>;
                        xlnx,r-xsize = <0x780>;
                        xlnx,r-xdiv = <0x2>;
                        xlnx,r-ysize = <0x438>;
                        xlnx,w-bufsize = <0x3>;
                        xlnx,edk-iptype = "PERIPHERAL";
                        xlnx,w-dsizebits = <0x17>;
                        xlnx,w-bufdepth = <0x800>;
                        status = "okay";
                        xlnx,axi-data-width = <0x80>;
                        clock-names = "I_R_rclk", "I_W_wclk", "S_AXI_ACLK";
                        xlnx,w-xstride = <0x780>;
                        xlnx,w-xsize = <0x780>;
                        xlnx,w-ysize = <0x438>;
                        xlnx,name = "uifdma_dbuf_0";
                        xlnx,r-bufdepth = <0x40>;
                        xlnx,r-datawidth = <0x20>;
                };

                axi_ethernet_0: ethernet@41000000 {
                        phandle = <0x7>;
                        xlnx,speed-1-2p5 = <0x3e8>;
                        xlnx,txlane1-placement = "0";
                        xlnx,ip-name = "axi_ethernet";
                        xlnx,is-gt-wiz-old = <0x0>;
                        reg = <0x41000000 0x40000>;
                        xlnx,include-io;
                        xlnx,rxmem = <0x1000>;
                        xlnx,tx-in-upper-nibble;
                        xlnx,axisclkrate = <0x0>;
                        xlnx,txmem = "0";
                        xlnx,mdio-board-interface = "0";
                        xlnx,phyaddr = <0x1>;
                        xlnx,supportlevel = <0x0>;
                        local-mac-address = [00 0A 23 00 00 00];
                        xlnx,diffclk-board-interface = "0";
                        xlnx,frame-filter;
                        axistream-connected = <&axi_dma_0>;
                        xlnx,phyrst-board-interface-dummy-port = "0";
                        interrupt-names = "interrupt", "mac_irq", "mm2s_introut", "s2mm_introut";
                        compatible = "xlnx,axi-ethernet-8.0", "xlnx,axi-ethernet-1.00.a", "xlnx,axi-ethernet-1.00.a";
                        xlnx,gt-type = "0";
                        xlnx,drpclkrate = <0x0>;
                        axistream-control-connected = <&axi_dma_0>;
                        interrupt-parent = <&intc>;
                        xlnx,versal-gt-board-flow = <0x0>;
                        xlnx,num-queues = /bits/ 16 <0x0001>;
                        xlnx,channel-ids = <0x1>;
                        max-speed = <0x3e8>;
                        status = "okay";
                        xlnx,timer-format = <0x0>;
                        xlnx,statistics-width = "0";
                        xlnx,name = "axi_ethernet_0";
                        interrupts = <0x0 0x20 0x4 0x0 0x1f 0x1 0x0 0x1d 0x4 0x0 0x1e 0x4>;
                        clocks = <&clkc 0xf>,
                         <&clkc 0x10>,
                         <&clkc 0x11>,
                         <&clkc 0xf>;
                        xlnx,gtrefclksrc = "0";
                        xlnx,rxcsum = <0x0>;
                        xlnx,statistics-counters;
                        xlnx,include-dre;
                        xlnx,edk-iptype = "0";
                        xlnx,gtrefclkrate = <0x0>;
                        xlnx,lvdsclkrate = <0x0>;
                        xlnx,number-of-table-entries = <0x0>;
                        clock-names = "axis_clk", "gtx_clk", "ref_clk", "s_axi_lite_clk";
                        xlnx,rxlane0-placement = "0";
                        xlnx,timer-clk-period = <0x0>;
                        xlnx,ethernet-board-interface = "0";
                        xlnx,txlane0-placement = "0";
                        xlnx,gtlocation = "0";
                        phy-mode = "rgmii";
                        xlnx,gt-settings = <0x0>;
                        xlnx,clockselection = "0";
                        xlnx,processor-mode;
                        xlnx,txcsum = <0x0>;
                        xlnx,phyrst-board-interface = "0";
                        xlnx,axiliteclkrate = <0x0>;
                        xlnx,rxlane1-placement = "0";

                        axi_ethernet_0_mdio: mdio {
                                phandle = <0x5a>;
                                #address-cells = <0x1>;
                                #size-cells = <0x0>;
                        };
                };

                axi_ethernet_1: ethernet@41040000 {
                        phandle = <0x8>;
                        xlnx,speed-1-2p5 = <0x3e8>;
                        xlnx,txlane1-placement = "0";
                        xlnx,ip-name = "axi_ethernet";
                        xlnx,is-gt-wiz-old = <0x0>;
                        reg = <0x41040000 0x40000>;
                        xlnx,include-io;
                        xlnx,rxmem = <0x1000>;
                        xlnx,tx-in-upper-nibble;
                        xlnx,axisclkrate = <0x0>;
                        xlnx,txmem = "0";
                        xlnx,mdio-board-interface = "0";
                        xlnx,phyaddr = <0x1>;
                        xlnx,supportlevel = <0x0>;
                        local-mac-address = [00 0A 23 00 00 01];
                        xlnx,diffclk-board-interface = "0";
                        xlnx,frame-filter;
                        axistream-connected = <&axi_ethernet_1_dma>;
                        xlnx,phyrst-board-interface-dummy-port = "0";
                        interrupt-names = "interrupt", "mac_irq", "mm2s_introut", "s2mm_introut";
                        compatible = "xlnx,axi-ethernet-8.0", "xlnx,axi-ethernet-1.00.a", "xlnx,axi-ethernet-1.00.a";
                        xlnx,gt-type = "0";
                        xlnx,drpclkrate = <0x0>;
                        axistream-control-connected = <&axi_ethernet_1_dma>;
                        interrupt-parent = <&intc>;
                        xlnx,versal-gt-board-flow = <0x0>;
                        xlnx,num-queues = /bits/ 16 <0x0001>;
                        xlnx,channel-ids = <0x1>;
                        max-speed = <0x3e8>;
                        status = "okay";
                        xlnx,timer-format = <0x0>;
                        xlnx,statistics-width = "0";
                        xlnx,name = "axi_ethernet_1";
                        interrupts = <0x0 0x22 0x4 0x0 0x21 0x1 0x0 0x23 0x4 0x0 0x24 0x4>;
                        clocks = <&clkc 0xf>,
                         <&misc_clk_0>,
                         <&misc_clk_0>,
                         <&clkc 0xf>;
                        xlnx,gtrefclksrc = "0";
                        xlnx,rxcsum = <0x0>;
                        xlnx,statistics-counters;
                        xlnx,include-dre;
                        xlnx,edk-iptype = "0";
                        xlnx,gtrefclkrate = <0x0>;
                        xlnx,lvdsclkrate = <0x0>;
                        xlnx,number-of-table-entries = <0x0>;
                        clock-names = "axis_clk", "gtx_clk", "gtx_clk90", "s_axi_lite_clk";
                        xlnx,rxlane0-placement = "0";
                        xlnx,timer-clk-period = <0x0>;
                        xlnx,ethernet-board-interface = "0";
                        xlnx,txlane0-placement = "0";
                        xlnx,gtlocation = "0";
                        phy-mode = "rgmii";
                        xlnx,gt-settings = <0x0>;
                        xlnx,clockselection = "0";
                        xlnx,processor-mode;
                        xlnx,txcsum = <0x0>;
                        xlnx,phyrst-board-interface = "0";
                        xlnx,axiliteclkrate = <0x0>;
                        xlnx,rxlane1-placement = "0";

                        axi_ethernet_1_mdio: mdio {
                                phandle = <0x5b>;
                                #address-cells = <0x1>;
                                #size-cells = <0x0>;
                        };
                };
        };

        ps7_qspi_linear_0_memory: memory@fc000000 {
                phandle = <0x1e>;
                compatible = "xlnx,ps7-qspi-linear-1.00.a-memory";
                xlnx,ip-name = "ps7_qspi_linear";
                device_type = "memory";
                memory_type = "linear_flash";
                reg = <0xfc000000 0x1000000>;
        };

        ps7_ddr_0_memory: memory@00100000 {
                phandle = <0x2>;
                compatible = "xlnx,ps7-ddr-1.00.a";
                xlnx,ip-name = "ps7_ddr";
                device_type = "memory";
                memory_type = "memory";
                reg = <0x100000 0x3ff00000>;
        };

        ps7_ram_0_memory: memory@0 {
                phandle = <0x3>;
                compatible = "xlnx,ps7-ram-1.00.a";
                xlnx,ip-name = "ps7_ram";
                device_type = "memory";
                memory_type = "memory";
                reg = <0x0 0x30000>;
        };

        ps7_ram_1_memory: memory@ffff0000 {
                phandle = <0x4>;
                compatible = "xlnx,ps7-ram-1.00.a";
                xlnx,ip-name = "ps7_ram";
                device_type = "memory";
                memory_type = "memory";
                reg = <0xffff0000 0xfe00>;
        };

        chosen {
                stdout-path = "serial0:115200n8";
        };

        aliases {
                serial0 = "/axi/serial@e0001000";
                ethernet1 = "/amba_pl/ethernet@41040000";
                spi0 = "/axi/spi@e000d000";
                serial1 = "/axi/coresight@f8800000";
                ethernet2 = "/axi/ethernet@e000b000";
                ethernet0 = "/amba_pl/ethernet@41000000";
        };

        __symbols__ {
                cpus_a9 = "/cpus-a9@0";
                ps7_cortexa9_0 = "/cpus-a9@0/cpu@0";
                ps7_cortexa9_1 = "/cpus-a9@0/cpu@1";
                fpga_full = "/fpga-region";
                regulator_vccpint = "/fixedregulator";
                replicator_out_port0 = "/replicator/out-ports/port@0/endpoint";
                replicator_out_port1 = "/replicator/out-ports/port@1/endpoint";
                replicator_in_port0 = "/replicator/in-ports/port/endpoint";
                amba = "/axi";
                adc = "/axi/adc@f8007100";
                gpio0 = "/axi/gpio@e000a000";
                intc = "/axi/interrupt-controller@f8f01000";
                L2 = "/axi/cache-controller@f8f02000";
                mc = "/axi/memory-controller@f8006000";
                ocm = "/axi/sram@fffc0000";
                uart1 = "/axi/serial@e0001000";
                qspi = "/axi/spi@e000d000";
                gem0 = "/axi/ethernet@e000b000";
                sdhci0 = "/axi/mmc@e0100000";
                sdhci1 = "/axi/mmc@e0101000";
                slcr = "/axi/slcr@f8000000";
                clkc = "/axi/slcr@f8000000/clkc@100";
                rstc = "/axi/slcr@f8000000/rstc@200";
                pinctrl0 = "/axi/slcr@f8000000/pinctrl@700";
                dmac_s = "/axi/dma-controller@f8003000";
                devcfg = "/axi/devcfg@f8007000";
                efuse = "/axi/efuse@f800d000";
                global_timer = "/axi/timer@f8f00200";
                scutimer = "/axi/timer@f8f00600";
                scuwdt = "/axi/scuwatchdog@f8f00620";
                usb0 = "/axi/usb@e0002000";
                watchdog0 = "/axi/watchdog@f8005000";
                coresight = "/axi/coresight@f8800000";
                etb_in_port = "/axi/etb@f8801000/in-ports/port/endpoint";
                tpiu_in_port = "/axi/tpiu@f8803000/in-ports/port/endpoint";
                funnel_out_port = "/axi/funnel@f8804000/out-ports/port/endpoint";
                funnel0_in_port0 = "/axi/funnel@f8804000/in-ports/port@0/endpoint";
                funnel0_in_port1 = "/axi/funnel@f8804000/in-ports/port@1/endpoint";
                ptm0_out_port = "/axi/ptm@f889c000/out-ports/port/endpoint";
                ptm1_out_port = "/axi/ptm@f889d000/out-ports/port/endpoint";
                ps7_pmu_0 = "/axi/ps7_pmu@f8891000";
                ps7_ocmc_0 = "/axi/ps7_ocmc@f800c000";
                ps7_gpv_0 = "/axi/ps7_gpv@f8900000";
                ps7_scuc_0 = "/axi/ps7_scuc@f8f00000";
                ps7_iop_bus_config_0 = "/axi/ps7_iop_bus_config@e0200000";
                ps7_dma_ns = "/axi/ps7_dma@f8004000";
                ps7_afi_0 = "/axi/ps7_afi@f8008000";
                ps7_afi_1 = "/axi/ps7_afi@f8009000";
                ps7_afi_2 = "/axi/ps7_afi@f800a000";
                ps7_afi_3 = "/axi/ps7_afi@f800b000";
                ps7_qspi_linear_0 = "/axi/ps7_qspi_linear@fc000000";
                amba_pl = "/amba_pl";
                clocking2 = "/amba_pl/clocking2";
                clocking1 = "/amba_pl/clocking1";
                clocking0 = "/amba_pl/clocking0";
                misc_clk_2 = "/amba_pl/misc_clk_2";
                misc_clk_1 = "/amba_pl/misc_clk_1";
                misc_clk_0 = "/amba_pl/misc_clk_0";
                axi_dma_0 = "/amba_pl/dma@40400000";
                axi_ethernet_1_dma = "/amba_pl/dma@40410000";
                axi_vdma_0 = "/amba_pl/dma@43000000";
                dma_channel_43000000 = "/amba_pl/dma@43000000/dma-channel@43000000";
                uifdma_dbuf_0 = "/amba_pl/uifdma_dbuf@43c00000";
                axi_ethernet_0 = "/amba_pl/ethernet@41000000";
                axi_ethernet_0_mdio = "/amba_pl/ethernet@41000000/mdio";
                axi_ethernet_1 = "/amba_pl/ethernet@41040000";
                axi_ethernet_1_mdio = "/amba_pl/ethernet@41040000/mdio";
                ps7_qspi_linear_0_memory = "/memory@fc000000";
                ps7_ddr_0_memory = "/memory@00100000";
                ps7_ram_0_memory = "/memory@0";
                ps7_ram_1_memory = "/memory@ffff0000";
        };
};
